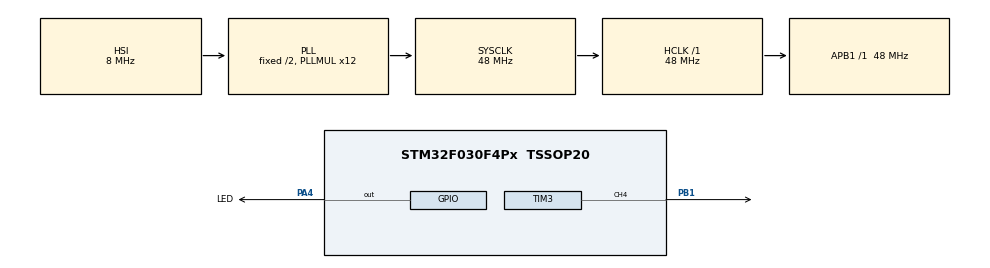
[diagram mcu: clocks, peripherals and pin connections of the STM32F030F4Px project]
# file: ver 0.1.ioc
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Mcu.Family=STM32F0
Mcu.Name=STM32F030F4Px
Mcu.Package=TSSOP20
NVIC.TIM3_IRQn=true\:0\:0\:false\:true\:true\:1\:true
PA0.Mode=SYS_WakeUp0
PA0.Signal=SYS_WKUP1
PA13.Mode=Serial_Wire
PA13.Signal=SYS_SWDIO
PA14.Mode=Serial_Wire
PA14.Signal=SYS_SWCLK
PA4.GPIO_Label=LED
PA4.GPIO_Speed=GPIO_SPEED_FREQ_HIGH
PA4.Signal=GPIO_Output
PB1.GPIO_Speed=GPIO_SPEED_FREQ_HIGH
PB1.Signal=S_TIM3_CH4
ProjectManager.HeapSize=0x200
ProjectManager.StackSize=0x400
ProjectManager.TargetToolchain=MDK-ARM V5
RCC.AHBFreq_Value=48000000
RCC.APB1Freq_Value=48000000
RCC.APB1TimFreq_Value=48000000
RCC.HCLKFreq_Value=48000000
RCC.PLLMUL=RCC_PLL_MUL12
RCC.SYSCLKFreq_VALUE=48000000
RCC.SYSCLKSource=RCC_SYSCLKSOURCE_PLLCLK
RCC.VDD_VALUE=2.4
SH.S_TIM3_CH4.0=TIM3_CH4,PWM Generation4 CH4
TIM3.AutoReloadPreload=TIM_AUTORELOAD_PRELOAD_ENABLE
TIM3.Channel-PWM\ Generation4\ CH4=TIM_CHANNEL_4
TIM3.Period=400
TIM3.Prescaler=48
TIM3.Pulse-PWM\ Generation4\ CH4=200
TIM3.TIM_MasterSlaveMode=TIM_MASTERSLAVEMODE_DISABLE
VP_TIM3_VS_ClockSourceINT.Mode=Internal
board=custom

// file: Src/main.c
/* USER CODE BEGIN Header */
/**
  ******************************************************************************
  * @file           : main.c
  * @brief          : Main program body
  ******************************************************************************
  ** This notice applies to any and all portions of this file
  * that are not between comment pairs USER CODE BEGIN and
  * USER CODE END. Other portions of this file, whether
  * inserted by the user or by software development tools
  * are owned by their respective copyright owners.
  *
  * COPYRIGHT(c) 2019 STMicroelectronics
  *
  * Redistribution and use in source and binary forms, with or without modification,
  * are permitted provided that the following conditions are met:
  *   1. Redistributions of source code must retain the above copyright notice,
  *      this list of conditions and the following disclaimer.
  *   2. Redistributions in binary form must reproduce the above copyright notice,
  *      this list of conditions and the following disclaimer in the documentation
  *      and/or other materials provided with the distribution.
  *   3. Neither the name of STMicroelectronics nor the names of its contributors
  *      may be used to endorse or promote products derived from this software
  *      without specific prior written permission.
  *
  * THIS SOFTWARE IS PROVIDED BY THE COPYRIGHT HOLDERS AND CONTRIBUTORS "AS IS"
  * AND ANY EXPRESS OR IMPLIED WARRANTIES, INCLUDING, BUT NOT LIMITED TO, THE
  * IMPLIED WARRANTIES OF MERCHANTABILITY AND FITNESS FOR A PARTICULAR PURPOSE ARE
  * DISCLAIMED. IN NO EVENT SHALL THE COPYRIGHT HOLDER OR CONTRIBUTORS BE LIABLE
  * FOR ANY DIRECT, INDIRECT, INCIDENTAL, SPECIAL, EXEMPLARY, OR CONSEQUENTIAL
  * DAMAGES (INCLUDING, BUT NOT LIMITED TO, PROCUREMENT OF SUBSTITUTE GOODS OR
  * SERVICES; LOSS OF USE, DATA, OR PROFITS; OR BUSINESS INTERRUPTION) HOWEVER
  * CAUSED AND ON ANY THEORY OF LIABILITY, WHETHER IN CONTRACT, STRICT LIABILITY,
  * OR TORT (INCLUDING NEGLIGENCE OR OTHERWISE) ARISING IN ANY WAY OUT OF THE USE
  * OF THIS SOFTWARE, EVEN IF ADVISED OF THE POSSIBILITY OF SUCH DAMAGE.
  *
  ******************************************************************************
  */
/* USER CODE END Header */

#include "main.h"

TIM_HandleTypeDef htim3;

/* USER CODE BEGIN PV */
uint8_t wkup1=0;

/* USER CODE END PV */

void SystemClock_Config(void);
static void MX_GPIO_Init(void);
static void MX_TIM3_Init(void);
static void MX_NVIC_Init(void);

/* USER CODE BEGIN PFP */
//void tone (int freq, int time_ms);

//void alarm(void);

void tone (int freq, int time_ms) {
    if (freq > 0) {
        TIM3->ARR = 1000000/freq;
        TIM3->CCR1 = TIM3->ARR / 2;
    }
    else {
        TIM3->ARR = 1000;
        TIM3->CCR1 = 0;
    }

    HAL_Delay(time_ms);
}

void alarm(void)
{
    HAL_TIM_Base_Start (&htim3);                  //START TIM2
    HAL_TIM_PWM_Start  (&htim3, TIM_CHANNEL_4);   //START PWM CH2
    tone(2500, 500);
    tone(1000, 500);
    tone(2500, 500);
    tone(1000, 500);
    HAL_Delay(1000);
    HAL_TIM_Base_Stop (&htim3);                  //START TIM2
    HAL_TIM_PWM_Stop  (&htim3, TIM_CHANNEL_4);   //START PWM CH2
}

/* USER CODE END PFP */

int main(void)
{

  /* MCU Configuration--------------------------------------------------------*/

  /* Reset of all peripherals, Initializes the Flash interface and the Systick. */
  HAL_Init();

  /* Configure the system clock */
  SystemClock_Config();

  /* Initialize all configured peripherals */
  MX_GPIO_Init();
  MX_TIM3_Init();

  /* Initialize interrupts */
  MX_NVIC_Init();
  /* USER CODE BEGIN 2 */

  //HAL_TIM_Base_Start (&htim3);                  //START TIM2
  //HAL_TIM_PWM_Start  (&htim3, TIM_CHANNEL_4);   //START PWM CH2

  /* USER CODE END 2 */

  /* Infinite loop */
  /* USER CODE BEGIN WHILE */

		//-----------------------------------------------------------------------
    //------------------Задержка на перепрошивку т.к. STUNDBY Sleep----------
    HAL_GPIO_WritePin(LED_GPIO_Port, LED_Pin, GPIO_PIN_SET);
    HAL_Delay(5000);
    HAL_GPIO_WritePin(LED_GPIO_Port, LED_Pin, GPIO_PIN_RESET);
    //-----------------------------------------------------------------------
    //-----------Конфигурируем WKUP pin -------------------------------------
    //-----------------------------------------------------------------------
    /* (1) Enable the peripheral clock of GPIOA */
    RCC->AHBENR |= RCC_AHBENR_GPIOAEN; /* (1) */
    HAL_PWR_EnableWakeUpPin(PWR_WAKEUP_PIN1);
    //-------------------------------------------------------------------------

		if(__HAL_PWR_GET_FLAG(PWR_FLAG_SB)==SET)
		{
			__HAL_PWR_CLEAR_FLAG(PWR_FLAG_SB);
			wkup1=1;
		}
		else{
			//---------------SLEEP-----------------------------------------------------
            wkup1=0;
            HAL_TIM_Base_Start(&htim3);                  //STOP TIM2
            HAL_TIM_PWM_Start (&htim3, TIM_CHANNEL_4);   //STOP PWM CH2
            tone(2500, 500);
            tone(20000, 500);
            tone(2500, 500);
            tone(20000, 500);
            tone(2500, 1000);
            TIM3->ARR = 0;
            TIM3->CCR1 = 0;
            HAL_TIM_Base_Stop (&htim3);                  //STOP TIM2
            HAL_TIM_PWM_Stop  (&htim3, TIM_CHANNEL_4);   //STOP PWM CH2
			__HAL_PWR_CLEAR_FLAG(PWR_FLAG_WU);
    	    __HAL_PWR_GET_FLAG(PWR_CSR_EWUP1);  //разрешаем вэйкап, то есть пробуждение по переднему фронту на А0
            HAL_PWR_EnterSTANDBYMode();         //Sleep   //уснули
	    //-------------------------------------------------------------------------

		}
    /*
	//---------------SLEEP-----------------------------------------------------
    __HAL_PWR_CLEAR_FLAG(PWR_FLAG_WU);
	__HAL_PWR_GET_FLAG(PWR_CSR_EWUP1);  //разрешаем вэйкап, то есть пробуждение по переднему фронту на А0
    HAL_PWR_EnterSTANDBYMode();         //Sleep   //уснули
	//-------------------------------------------------------------------------
  */
	while (1)
  {

    if(wkup1==1)
    {
        HAL_GPIO_WritePin(LED_GPIO_Port, LED_Pin, GPIO_PIN_SET);
        alarm();
        HAL_GPIO_WritePin(LED_GPIO_Port, LED_Pin, GPIO_PIN_RESET);
        /*
        if (!(HAL_GPIO_ReadPin(GPIOA, GPIO_PIN_0)))
        {
            wkup1=0;
            HAL_GPIO_WritePin(LED_GPIO_Port, LED_Pin, GPIO_PIN_RESET);
        }
        */
    }

    /* USER CODE END WHILE */

  }
}

void SystemClock_Config(void)
{
  RCC_OscInitTypeDef RCC_OscInitStruct = {0};
  RCC_ClkInitTypeDef RCC_ClkInitStruct = {0};

  /**Initializes the CPU, AHB and APB busses clocks
  */
  RCC_OscInitStruct.OscillatorType = RCC_OSCILLATORTYPE_HSI;
  RCC_OscInitStruct.HSIState = RCC_HSI_ON;
  RCC_OscInitStruct.HSICalibrationValue = RCC_HSICALIBRATION_DEFAULT;
  RCC_OscInitStruct.PLL.PLLState = RCC_PLL_ON;
  RCC_OscInitStruct.PLL.PLLSource = RCC_PLLSOURCE_HSI;
  RCC_OscInitStruct.PLL.PLLMUL = RCC_PLL_MUL12;
  RCC_OscInitStruct.PLL.PREDIV = RCC_PREDIV_DIV1;
  if (HAL_RCC_OscConfig(&RCC_OscInitStruct) != HAL_OK)
  {
    Error_Handler();
  }
  /**Initializes the CPU, AHB and APB busses clocks
  */
  RCC_ClkInitStruct.ClockType = RCC_CLOCKTYPE_HCLK|RCC_CLOCKTYPE_SYSCLK
                              |RCC_CLOCKTYPE_PCLK1;
  RCC_ClkInitStruct.SYSCLKSource = RCC_SYSCLKSOURCE_PLLCLK;
  RCC_ClkInitStruct.AHBCLKDivider = RCC_SYSCLK_DIV1;
  RCC_ClkInitStruct.APB1CLKDivider = RCC_HCLK_DIV1;

  if (HAL_RCC_ClockConfig(&RCC_ClkInitStruct, FLASH_LATENCY_1) != HAL_OK)
  {
    Error_Handler();
  }
}

/**
  * @brief NVIC Configuration.
  * @retval None
  */
static void MX_NVIC_Init(void)
{
  /* TIM3_IRQn interrupt configuration */
  HAL_NVIC_SetPriority(TIM3_IRQn, 0, 0);
  HAL_NVIC_EnableIRQ(TIM3_IRQn);
}

static void MX_TIM3_Init(void)
{

  TIM_ClockConfigTypeDef sClockSourceConfig = {0};
  TIM_MasterConfigTypeDef sMasterConfig = {0};
  TIM_OC_InitTypeDef sConfigOC = {0};

  htim3.Instance = TIM3;
  htim3.Init.Prescaler = 48; //48 !!!! 1000000Hz
  htim3.Init.CounterMode = TIM_COUNTERMODE_UP;
  htim3.Init.Period = 10000; //10000 100Hz min;   ;!!!400 2500Hz Rezonance!!!;     200 MAX
  htim3.Init.ClockDivision = TIM_CLOCKDIVISION_DIV1;
  htim3.Init.AutoReloadPreload = TIM_AUTORELOAD_PRELOAD_ENABLE;
  if (HAL_TIM_Base_Init(&htim3) != HAL_OK)
  {
    Error_Handler();
  }
  sClockSourceConfig.ClockSource = TIM_CLOCKSOURCE_INTERNAL;
  if (HAL_TIM_ConfigClockSource(&htim3, &sClockSourceConfig) != HAL_OK)
  {
    Error_Handler();
  }
  if (HAL_TIM_PWM_Init(&htim3) != HAL_OK)
  {
    Error_Handler();
  }
  sMasterConfig.MasterOutputTrigger = TIM_TRGO_RESET;
  sMasterConfig.MasterSlaveMode = TIM_MASTERSLAVEMODE_DISABLE;
  if (HAL_TIMEx_MasterConfigSynchronization(&htim3, &sMasterConfig) != HAL_OK)
  {
    Error_Handler();
  }
  sConfigOC.OCMode = TIM_OCMODE_PWM1;
  sConfigOC.Pulse = 200;
  sConfigOC.OCPolarity = TIM_OCPOLARITY_HIGH;
  sConfigOC.OCFastMode = TIM_OCFAST_DISABLE;
  if (HAL_TIM_PWM_ConfigChannel(&htim3, &sConfigOC, TIM_CHANNEL_4) != HAL_OK)
  {
    Error_Handler();
  }
  HAL_TIM_MspPostInit(&htim3);

}

static void MX_GPIO_Init(void)
{
  GPIO_InitTypeDef GPIO_InitStruct = {0};

  /* GPIO Ports Clock Enable */
  __HAL_RCC_GPIOA_CLK_ENABLE();
  __HAL_RCC_GPIOB_CLK_ENABLE();

  /*Configure GPIO pin Output Level */
  HAL_GPIO_WritePin(LED_GPIO_Port, LED_Pin, GPIO_PIN_RESET);

  /*Configure GPIO pin : LED_Pin */
  GPIO_InitStruct.Pin = LED_Pin;
  GPIO_InitStruct.Mode = GPIO_MODE_OUTPUT_PP;
  GPIO_InitStruct.Pull = GPIO_NOPULL;
  GPIO_InitStruct.Speed = GPIO_SPEED_FREQ_HIGH;
  HAL_GPIO_Init(LED_GPIO_Port, &GPIO_InitStruct);

}

/* USER CODE BEGIN 4 */

/**
  * @brief  This function handles EXTI0_1 interrupt request.
  * @param  None
  * @retval None
  */

/* USER CODE END 4 */

void Error_Handler(void)
{
}

/************************ (C) COPYRIGHT STMicroelectronics *****END OF FILE****/
